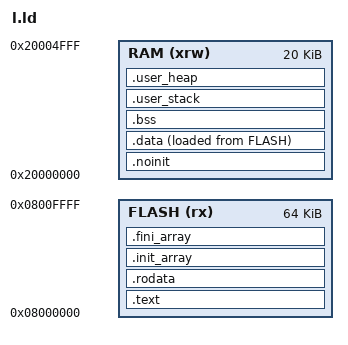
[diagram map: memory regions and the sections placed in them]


/*
******************************************************************************
**
** @file        : l.ld
**
** @author      : Auto-generated by lds-maker
**
** @brief       : Linker script for STM32F103C8Tx Device from STM32F1 series
**                      64KBytes FLASH
**                      20KBytes RAM
**
**                Set heap size, stack size and stack location according
**                to application requirements.
**
**                Set memory bank area and size if external memory is used
**
**  Target      : STMicroelectronics STM32
**
**  Distribution: The file is distributed as is, without any warranty
**                of any kind.
**
******************************************************************************
** @attention
**
** Copyright (c) 2023 STMicroelectronics.
** All rights reserved.
**
** This software is licensed under terms that can be found in the LICENSE file
** in the root directory of this software component.
** If no LICENSE file comes with this software, it is provided AS-IS.
**
******************************************************************************
*/

/* Memories definition */
MEMORY
{
  FLASH    (rx)    : ORIGIN = 0x8000000,   LENGTH = 64K
  RAM    (xrw)    : ORIGIN = 0x20000000,   LENGTH = 20K
}


/* Enforce emmition of the vector table. */
EXTERN (vector_table)

/* Entry Point */
ENTRY(_start)

/* This provide weak linking to empty handlers, which can be overridden */
__stack_size__ = 0x800;
__heap_size__ = 0x400;
PROVIDE(_stack = ORIGIN(RAM) + LENGTH(RAM));

/* Sections */
SECTIONS
{
  .text : {
    *(.vectors)  /* Vector table */
    *(.text*)  /* Program code */
    . = ALIGN(4);
  } >FLASH

  .rodata : {
    *(.rodata*)  /* Read-only data */
    . = ALIGN(4);
  } >FLASH

  .init_array : {
    . = ALIGN(4);
    KEEP (*(SORT(.init_array.*)))
    KEEP (*(.init_array))
  } >FLASH

  .fini_array : {
    . = ALIGN(4);
    KEEP (*(.fini_array))
    KEEP (*(SORT(.fini_array.*)))
  } >FLASH

  /* RAM, but not cleared on reset, eg boot/app comms */
  .noinit (NOLOAD) : {
    *(.noinit*)
  } >RAM
  . = ALIGN(4);

  .data : {
    __data_start__ = .;
    *(.data*)  /* Read-write initialized data */
    *(.ramtext*)    /* "text" functions to run in RAM */
    . = ALIGN(4);
    __data_end__ = .;
  } >RAM AT >FLASH
  __data_loadaddr__ = LOADADDR(.data);

  .bss : {
    __bss_start__ = .;
    *(.bss*)  /* Read-write zero initialized data */
    *(COMMON)
    . = ALIGN(4);
    __bss_end__ = .;
  } >RAM

  .user_stack :{
    __user_stack_start__ = .;
    . = . + __stack_size__;
    . = ALIGN(4);
    __user_stack_end__ = .;
  } >RAM

  .user_heap :{
    __user_heap_start__ = .;
    . = . + __heap_size__;
    . = ALIGN(4);
    __user_heap_end__ = .;
  } >RAM

  /*
   * The .eh_frame section appears to be used for C++ exception handling.
   * You may need to fix this if you're using C++.
   */
  /DISCARD/ : { *(.eh_frame) }
}
